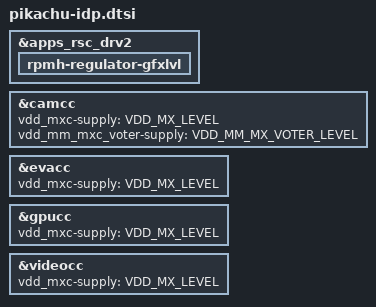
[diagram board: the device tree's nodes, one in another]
// SPDX-License-Identifier: BSD-3-Clause
/*
 * Copyright (c) Qualcomm Technologies, Inc. and/or its subsidiaries.
 */

#include "pikachu-idp-base.dtsi"
#include "pikachu-pmic-overlay.dtsi"
#include "pikachu-qpt-overlay.dtsi"
#include "pikachu-thermal-overlay.dtsi"

&apps_rsc_drv2 {
	rpmh-regulator-gfxlvl {
		status = "okay";
	};
};

&camcc {
	vdd_mxc-supply = <&VDD_MX_LEVEL>;
	vdd_mm_mxc_voter-supply = <&VDD_MM_MX_VOTER_LEVEL>;
};

&evacc {
	vdd_mxc-supply = <&VDD_MX_LEVEL>;
};

&gpucc {
	vdd_mxc-supply = <&VDD_MX_LEVEL>;
};

&videocc {
	vdd_mxc-supply = <&VDD_MX_LEVEL>;
};
